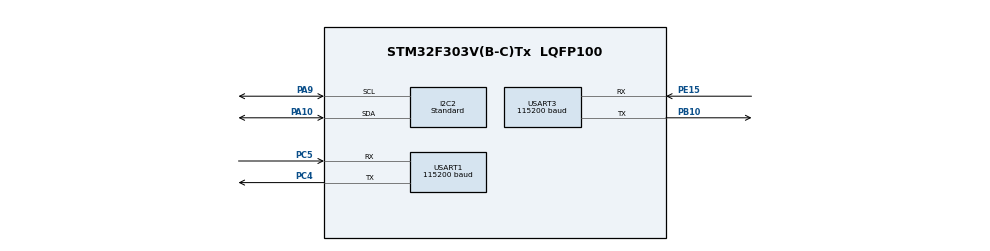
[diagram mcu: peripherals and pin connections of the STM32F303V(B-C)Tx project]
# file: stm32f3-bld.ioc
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Dma.Request0=USART1_RX
Dma.Request1=USART1_TX
Dma.Request2=USART3_RX
Dma.Request3=USART3_TX
Dma.USART1_RX.0.Direction=DMA_PERIPH_TO_MEMORY
Dma.USART1_RX.0.Instance=DMA1_Channel5
Dma.USART1_RX.0.MemDataAlignment=DMA_MDATAALIGN_BYTE
Dma.USART1_RX.0.MemInc=DMA_MINC_ENABLE
Dma.USART1_RX.0.Mode=DMA_CIRCULAR
Dma.USART1_RX.0.PeriphDataAlignment=DMA_PDATAALIGN_BYTE
Dma.USART1_RX.0.PeriphInc=DMA_PINC_DISABLE
Dma.USART1_RX.0.Priority=DMA_PRIORITY_LOW
Dma.USART1_TX.1.Direction=DMA_MEMORY_TO_PERIPH
Dma.USART1_TX.1.Instance=DMA1_Channel4
Dma.USART1_TX.1.MemDataAlignment=DMA_MDATAALIGN_BYTE
Dma.USART1_TX.1.MemInc=DMA_MINC_ENABLE
Dma.USART1_TX.1.Mode=DMA_NORMAL
Dma.USART1_TX.1.PeriphDataAlignment=DMA_PDATAALIGN_BYTE
Dma.USART1_TX.1.PeriphInc=DMA_PINC_DISABLE
Dma.USART1_TX.1.Priority=DMA_PRIORITY_LOW
Dma.USART3_RX.2.Direction=DMA_PERIPH_TO_MEMORY
Dma.USART3_RX.2.Instance=DMA1_Channel3
Dma.USART3_RX.2.MemDataAlignment=DMA_MDATAALIGN_BYTE
Dma.USART3_RX.2.MemInc=DMA_MINC_ENABLE
Dma.USART3_RX.2.Mode=DMA_CIRCULAR
Dma.USART3_RX.2.PeriphDataAlignment=DMA_PDATAALIGN_BYTE
Dma.USART3_RX.2.PeriphInc=DMA_PINC_DISABLE
Dma.USART3_RX.2.Priority=DMA_PRIORITY_LOW
Dma.USART3_TX.3.Direction=DMA_MEMORY_TO_PERIPH
Dma.USART3_TX.3.Instance=DMA1_Channel2
Dma.USART3_TX.3.MemDataAlignment=DMA_MDATAALIGN_BYTE
Dma.USART3_TX.3.MemInc=DMA_MINC_ENABLE
Dma.USART3_TX.3.Mode=DMA_NORMAL
Dma.USART3_TX.3.PeriphDataAlignment=DMA_PDATAALIGN_BYTE
Dma.USART3_TX.3.PeriphInc=DMA_PINC_DISABLE
Dma.USART3_TX.3.Priority=DMA_PRIORITY_LOW
I2C2.I2C_Speed_Mode=I2C_Standard
I2C2.Timing=0x10808DD3
IWDG.Prescaler=IWDG_PRESCALER_128
IWDG.Reload=3125
IWDG.Window=3125
Mcu.Family=STM32F3
Mcu.Name=STM32F303V(B-C)Tx
Mcu.Package=LQFP100
NVIC.DMA1_Channel2_IRQn=true\:1\:2\:true\:false\:true\:false\:true\:true
NVIC.DMA1_Channel3_IRQn=true\:1\:1\:true\:false\:true\:false\:true\:true
NVIC.DMA1_Channel4_IRQn=true\:1\:2\:true\:false\:true\:false\:true\:true
NVIC.DMA1_Channel5_IRQn=true\:1\:1\:true\:false\:true\:false\:true\:true
NVIC.I2C2_ER_IRQn=true\:0\:0\:false\:false\:true\:true\:true\:true
NVIC.I2C2_EV_IRQn=true\:0\:0\:false\:false\:true\:true\:true\:true
NVIC.PriorityGroup=NVIC_PRIORITYGROUP_2
NVIC.USART1_IRQn=true\:1\:0\:true\:false\:true\:true\:true\:true
NVIC.USART3_IRQn=true\:1\:0\:true\:false\:true\:true\:true\:true
PA10.Mode=I2C
PA10.Signal=I2C2_SDA
PA13.Mode=Serial_Wire
PA13.Signal=SYS_JTMS-SWDIO
PA14.Mode=Serial_Wire
PA14.Signal=SYS_JTCK-SWCLK
PA9.Mode=I2C
PA9.Signal=I2C2_SCL
PB10.Mode=Asynchronous
PB10.Signal=USART3_TX
PC4.Mode=Asynchronous
PC4.Signal=USART1_TX
PC5.Mode=Asynchronous
PC5.Signal=USART1_RX
PE15.Mode=Asynchronous
PE15.Signal=USART3_RX
PF0-OSC_IN.Mode=HSE-External-Clock-Source
PF0-OSC_IN.Signal=RCC_OSC_IN
PF1-OSC_OUT.Signal=RCC_OSC_OUT
ProjectManager.HeapSize=0x400
ProjectManager.StackSize=0x800
ProjectManager.TargetToolchain=Makefile
RCC.AHBFreq_Value=72000000
RCC.APB1CLKDivider=RCC_HCLK_DIV2
RCC.APB1Freq_Value=36000000
RCC.APB1TimFreq_Value=72000000
RCC.APB2Freq_Value=72000000
RCC.APB2TimFreq_Value=72000000
RCC.CortexFreq_Value=72000000
RCC.HCLKFreq_Value=72000000
RCC.HSE_VALUE=8000000
RCC.HSI_VALUE=8000000
RCC.I2c1ClockSelection=RCC_I2C1CLKSOURCE_SYSCLK
RCC.I2c2ClockSelection=RCC_I2C2CLKSOURCE_SYSCLK
RCC.LSE_VALUE=32768
RCC.PLLMUL=RCC_PLL_MUL9
RCC.PLLSourceVirtual=RCC_PLLSOURCE_HSE
RCC.PRESCALERUSB=RCC_USBCLKSOURCE_PLL_DIV1_5
RCC.SYSCLKFreq_VALUE=72000000
RCC.SYSCLKSourceVirtual=RCC_SYSCLKSOURCE_PLLCLK
RCC.USBFreq_Value=48000000
RCC.Usart1ClockSelection=RCC_USART1CLKSOURCE_SYSCLK
RCC.Usart3ClockSelection=RCC_USART3CLKSOURCE_SYSCLK
USART1.BaudRate=115200
USART1.VirtualMode-Asynchronous=VM_ASYNC
USART3.BaudRate=115200
USART3.VirtualMode-Asynchronous=VM_ASYNC
VP_CRC_VS_CRC.Mode=CRC_Activate
VP_IWDG_VS_IWDG.Mode=IWDG_Activate
board=custom

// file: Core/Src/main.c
/* USER CODE BEGIN Header */
/**
  ******************************************************************************
  * @file           : main.c
  * @brief          : Main program body
  ******************************************************************************
  * @attention
  *
  * Copyright (c) 2023 STMicroelectronics.
  * All rights reserved.
  *
  * This software is licensed under terms that can be found in the LICENSE file
  * in the root directory of this software component.
  * If no LICENSE file comes with this software, it is provided AS-IS.
  *
  ******************************************************************************
  */
/* USER CODE END Header */
#include "main.h"
#include "crc.h"
#include "dma.h"
#include "i2c.h"
#include "iwdg.h"
#include "usart.h"
#include "gpio.h"

/* USER CODE BEGIN Includes */
#include "uart_device.h"
#include "i2c_slave.h"
#include "param.h"
#include "task.h"
#include "update.h"
/* USER CODE END Includes */

void SystemClock_Config(void);

int main(void)
{
  /* USER CODE BEGIN 1 */
  SCB->VTOR = ADDR_BASE_BLD;
  /* USER CODE END 1 */

  /* MCU Configuration--------------------------------------------------------*/

  /* Reset of all peripherals, Initializes the Flash interface and the Systick. */
  HAL_Init();

  /* Configure the system clock */
  SystemClock_Config();

  /* Initialize all configured peripherals */
  MX_GPIO_Init();
  MX_DMA_Init();
  MX_USART1_UART_Init();
  MX_CRC_Init();
  MX_IWDG_Init();
  MX_I2C2_Init();
  MX_USART3_UART_Init();
  /* USER CODE BEGIN 2 */
  uart_config(DEV_USART1);
  uart_config(DEV_USART3);
  i2c_slave_config();
  boot_param_check(1);
  /* USER CODE END 2 */

  /* Infinite loop */
  /* USER CODE BEGIN WHILE */
  sys_param_init();
  task_init();

  while (1)
  {
    // 任务事件循环
    task_loop();
    /* USER CODE END WHILE */

    /* USER CODE BEGIN 3 */
    LL_IWDG_ReloadCounter(IWDG);
  }
  /* USER CODE END 3 */
}

void SystemClock_Config(void)
{
  LL_FLASH_SetLatency(LL_FLASH_LATENCY_2);
  while(LL_FLASH_GetLatency()!= LL_FLASH_LATENCY_2)
  {
  }
  LL_RCC_HSE_EnableBypass();
  LL_RCC_HSE_Enable();

   /* Wait till HSE is ready */
  while(LL_RCC_HSE_IsReady() != 1)
  {

  }
  LL_RCC_LSI_Enable();

   /* Wait till LSI is ready */
  while(LL_RCC_LSI_IsReady() != 1)
  {

  }
  LL_RCC_PLL_ConfigDomain_SYS(LL_RCC_PLLSOURCE_HSE_DIV_1, LL_RCC_PLL_MUL_9);
  LL_RCC_PLL_Enable();

   /* Wait till PLL is ready */
  while(LL_RCC_PLL_IsReady() != 1)
  {

  }
  LL_RCC_SetAHBPrescaler(LL_RCC_SYSCLK_DIV_1);
  LL_RCC_SetAPB1Prescaler(LL_RCC_APB1_DIV_2);
  LL_RCC_SetAPB2Prescaler(LL_RCC_APB2_DIV_1);
  LL_RCC_SetSysClkSource(LL_RCC_SYS_CLKSOURCE_PLL);

   /* Wait till System clock is ready */
  while(LL_RCC_GetSysClkSource() != LL_RCC_SYS_CLKSOURCE_STATUS_PLL)
  {

  }
  LL_SetSystemCoreClock(72000000);

   /* Update the time base */
  if (HAL_InitTick (TICK_INT_PRIORITY) != HAL_OK)
  {
    Error_Handler();
  }
  LL_RCC_SetUSARTClockSource(LL_RCC_USART1_CLKSOURCE_SYSCLK);
  LL_RCC_SetUSARTClockSource(LL_RCC_USART3_CLKSOURCE_SYSCLK);
  LL_RCC_SetI2CClockSource(LL_RCC_I2C2_CLKSOURCE_SYSCLK);
}

void Error_Handler(void)
{
  __disable_irq();
  while (1)
  {
  }
}
